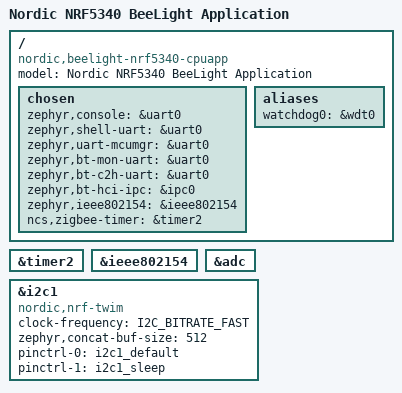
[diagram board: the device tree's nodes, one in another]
/*
 * Copyright (c) 2025 Daniel Kampert
 *
 * SPDX-License-Identifier: Apache-2.0
 */

#include "beelight_common-pinctrl.dtsi"

/ {
    model = "Nordic NRF5340 BeeLight Application";
    compatible = "nordic,beelight-nrf5340-cpuapp";

    chosen {
        zephyr,console = &uart0;
        zephyr,shell-uart = &uart0;
        zephyr,uart-mcumgr = &uart0;
        zephyr,bt-mon-uart = &uart0;
        zephyr,bt-c2h-uart = &uart0;
        zephyr,bt-hci-ipc = &ipc0;
        zephyr,ieee802154 = &ieee802154;
        ncs,zigbee-timer = &timer2;
    };

    aliases {
        watchdog0 = &wdt0;
    };
};

&timer2 {
    status = "okay";
};

&ieee802154 {
    status = "okay";
};

&adc {
    status = "okay";
};

&i2c1 {
    status = "okay";
    compatible = "nordic,nrf-twim";
    clock-frequency = <I2C_BITRATE_FAST>;
    zephyr,concat-buf-size = <512>;
    pinctrl-0 = <&i2c1_default>;
    pinctrl-1 = <&i2c1_sleep>;
    pinctrl-names = "default", "sleep";
};
